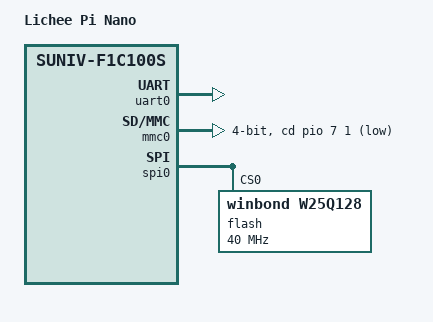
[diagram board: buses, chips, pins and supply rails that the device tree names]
// SPDX-License-Identifier: (GPL-2.0+ OR X11)
/*
 * Copyright 2018 Icenowy Zheng <icenowy@aosc.io>
 */

/dts-v1/;
#include "suniv-f1c100s.dtsi"
#include <dt-bindings/gpio/gpio.h>

/ {
	model = "Lichee Pi Nano";
	compatible = "licheepi,licheepi-nano", "allwinner,suniv-f1c100s";

	aliases {
		serial0 = &uart0;
	};

	chosen {
		stdout-path = "serial0:115200n8";
	};
};

&uart0 {
	pinctrl-names = "default";
	pinctrl-0 = <&uart0_pe_pins>;
	status = "okay";
};

&mmc0 {
	bus-width = <4>;
	cd-gpios = <&pio 7 1 GPIO_ACTIVE_LOW>; /* PH1 */
	status = "okay";
};

&spi0 {
	pinctrl-names = "default";
	pinctrl-0 = <&spi0_pins_a>;
	status = "okay";

	flash@0 {
		#address-cells = <1>;
		#size-cells = <1>;
		compatible = "winbond,w25q128", "jedec,spi-nor";
		reg = <0>;
		spi-max-frequency = <40000000>;
	};
};
